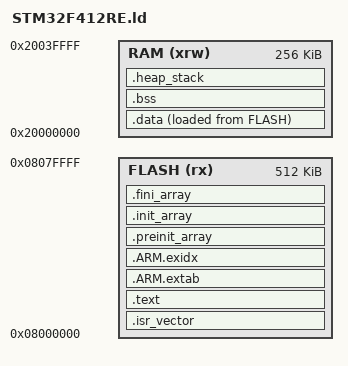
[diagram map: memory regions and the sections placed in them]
/* Selected STM32F412RET6: 512 KiB FLASH, 256 KiB contiguous SRAM.
 * Compile-only disabled image; board peripherals/physical qualification remain blocked.
 * Source: ST STM32F412xE/G datasheet, STM32F412RE product page. */
ENTRY(Reset_Handler)
MEMORY { FLASH (rx) : ORIGIN = 0x08000000, LENGTH = 512K
         RAM (xrw) : ORIGIN = 0x20000000, LENGTH = 256K }
_estack = ORIGIN(RAM) + LENGTH(RAM);
_Min_Heap_Size = 0x400;
_Min_Stack_Size = 0x1000;
SECTIONS {
 .isr_vector : { KEEP(*(.isr_vector)) } >FLASH
 .text : { *(.text*) *(.rodata*) KEEP(*(.init)) KEEP(*(.fini)) . = ALIGN(4); _etext = .; } >FLASH
 .ARM.extab : { *(.ARM.extab*) } >FLASH
 .ARM.exidx : { __exidx_start = .; *(.ARM.exidx*) __exidx_end = .; } >FLASH
 .preinit_array : { PROVIDE_HIDDEN(__preinit_array_start = .); KEEP(*(.preinit_array*)) PROVIDE_HIDDEN(__preinit_array_end = .); } >FLASH
 .init_array : { PROVIDE_HIDDEN(__init_array_start = .); KEEP(*(SORT(.init_array.*))) KEEP(*(.init_array)) PROVIDE_HIDDEN(__init_array_end = .); } >FLASH
 .fini_array : { PROVIDE_HIDDEN(__fini_array_start = .); KEEP(*(SORT(.fini_array.*))) KEEP(*(.fini_array)) PROVIDE_HIDDEN(__fini_array_end = .); } >FLASH
 _sidata = LOADADDR(.data);
 .data : { . = ALIGN(4); _sdata = .; *(.data*) . = ALIGN(4); _edata = .; } >RAM AT>FLASH
 .bss : { . = ALIGN(4); _sbss = .; *(.bss*) *(COMMON) . = ALIGN(4); _ebss = .; } >RAM
 .heap_stack : { . = ALIGN(8); PROVIDE(end = .); PROVIDE(_end = .); . += _Min_Heap_Size + _Min_Stack_Size; . = ALIGN(8); } >RAM
}
